AUTOSAR XML (schema 4-2-2)
package /STELLANTIS/EPT/ASWCs
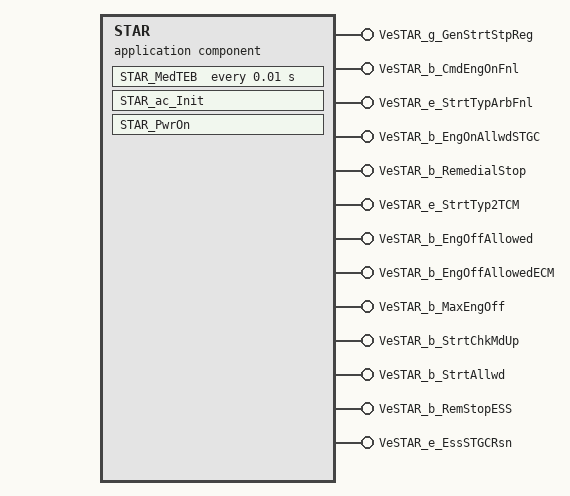
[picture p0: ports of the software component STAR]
  application sw component type STAR
    13 x provide port:
      VeSTAR_g_GenStrtStpReg: nonqueued-sender-com-spec{data-element=Value, init-value=0}, provided-interface=VeSTAR_g_GenStrtStpReg
      VeSTAR_b_CmdEngOnFnl: nonqueued-sender-com-spec{data-element=Value, init-value=0}, provided-interface=VeSTAR_b_CmdEngOnFnl
      VeSTAR_e_StrtTypArbFnl: nonqueued-sender-com-spec{data-element=Value, init-value=CeSTRR_e_NoAction}, provided-interface=VeSTAR_e_StrtTypArbFnl
      VeSTAR_b_EngOnAllwdSTGC: nonqueued-sender-com-spec{data-element=Value, init-value=0}, provided-interface=VeSTAR_b_EngOnAllwdSTGC
      VeSTAR_b_RemedialStop: nonqueued-sender-com-spec{data-element=Value, init-value=0}, provided-interface=VeSTAR_b_RemedialStop
      VeSTAR_e_StrtTyp2TCM: nonqueued-sender-com-spec{data-element=Value, init-value=CeSTRR_e_NoAction}, provided-interface=VeSTAR_e_StrtTyp2TCM
      VeSTAR_b_EngOffAllowed: nonqueued-sender-com-spec{data-element=Value, init-value=0}, provided-interface=VeSTAR_b_EngOffAllowed
      VeSTAR_b_EngOffAllowedECM: nonqueued-sender-com-spec{data-element=Value, init-value=0}, provided-interface=VeSTAR_b_EngOffAllowedECM
      VeSTAR_b_MaxEngOff: nonqueued-sender-com-spec{data-element=Value, init-value=0}, provided-interface=VeSTAR_b_MaxEngOff
      VeSTAR_b_StrtChkMdUp: nonqueued-sender-com-spec{data-element=Value, init-value=0}, provided-interface=VeSTAR_b_StrtChkMdUp
      VeSTAR_b_StrtAllwd: nonqueued-sender-com-spec{data-element=Value, init-value=0}, provided-interface=VeSTAR_b_StrtAllwd
      VeSTAR_b_RemStopESS: nonqueued-sender-com-spec{data-element=Value, init-value=0}, provided-interface=VeSTAR_b_RemStopESS
      VeSTAR_e_EssSTGCRsn: nonqueued-sender-com-spec{data-element=Value, init-value=CeSTRR_e_None}, provided-interface=VeSTAR_e_EssSTGCRsn
    behavior IB_STAR: data-type-mapping=msADTtoIDTMapping, handle-termination-and-restart=NO-SUPPORT
      timing event Event_MedTEB: start-on-event=STAR_MedTEB, period=0.01
      init event Event_STAR_ac_Init: start-on-event=STAR_ac_Init
      init event Event_PwrOn: start-on-event=STAR_PwrOn
      runnable STAR_ac_Init
        data-send-points:
          access OUT_VeSTAR_e_StrtTypArbFnl_Value: accessed-variable=VeSTAR_e_StrtTypArbFnl.Value
          access OUT_VeSTAR_e_StrtTyp2TCM_Value: accessed-variable=VeSTAR_e_StrtTyp2TCM.Value
          access OUT_VeSTAR_e_EssSTGCRsn_Value: accessed-variable=VeSTAR_e_EssSTGCRsn.Value
      runnable STAR_MedTEB
        data-send-points:
          13 x access:
            OUT_VeSTAR_b_EngOffAllowedECM_Value: accessed-variable=VeSTAR_b_EngOffAllowedECM.Value
            OUT_VeSTAR_b_MaxEngOff_Value: accessed-variable=VeSTAR_b_MaxEngOff.Value
            OUT_VeSTAR_b_StrtChkMdUp_Value: accessed-variable=VeSTAR_b_StrtChkMdUp.Value
            OUT_VeSTAR_e_EssSTGCRsn_Value: accessed-variable=VeSTAR_e_EssSTGCRsn.Value
            OUT_VeSTAR_e_StrtTypArbFnl_Value: accessed-variable=VeSTAR_e_StrtTypArbFnl.Value
            OUT_VeSTAR_e_StrtTyp2TCM_Value: accessed-variable=VeSTAR_e_StrtTyp2TCM.Value
            OUT_VeSTAR_b_StrtAllwd_Value: accessed-variable=VeSTAR_b_StrtAllwd.Value
            OUT_VeSTAR_b_CmdEngOnFnl_Value: accessed-variable=VeSTAR_b_CmdEngOnFnl.Value
            OUT_VeSTAR_b_EngOnAllwdSTGC_Value: accessed-variable=VeSTAR_b_EngOnAllwdSTGC.Value
            OUT_VeSTAR_b_RemedialStop_Value: accessed-variable=VeSTAR_b_RemedialStop.Value
            OUT_VeSTAR_b_EngOffAllowed_Value: accessed-variable=VeSTAR_b_EngOffAllowed.Value
            OUT_VeSTAR_b_RemStopESS_Value: accessed-variable=VeSTAR_b_RemStopESS.Value
            OUT_VeSTAR_g_GenStrtStpReg_Value: accessed-variable=VeSTAR_g_GenStrtStpReg.Value
      runnable STAR_PwrOn
        data-send-points:
          13 x access:
            OUT_VeSTAR_g_GenStrtStpReg_Value: accessed-variable=VeSTAR_g_GenStrtStpReg.Value
            OUT_VeSTAR_b_CmdEngOnFnl_Value: accessed-variable=VeSTAR_b_CmdEngOnFnl.Value
            OUT_VeSTAR_e_StrtTypArbFnl_Value: accessed-variable=VeSTAR_e_StrtTypArbFnl.Value
            OUT_VeSTAR_b_EngOnAllwdSTGC_Value: accessed-variable=VeSTAR_b_EngOnAllwdSTGC.Value
            OUT_VeSTAR_b_RemedialStop_Value: accessed-variable=VeSTAR_b_RemedialStop.Value
            OUT_VeSTAR_e_StrtTyp2TCM_Value: accessed-variable=VeSTAR_e_StrtTyp2TCM.Value
            OUT_VeSTAR_b_EngOffAllowed_Value: accessed-variable=VeSTAR_b_EngOffAllowed.Value
            OUT_VeSTAR_b_EngOffAllowedECM_Value: accessed-variable=VeSTAR_b_EngOffAllowedECM.Value
            OUT_VeSTAR_b_MaxEngOff_Value: accessed-variable=VeSTAR_b_MaxEngOff.Value
            OUT_VeSTAR_b_StrtChkMdUp_Value: accessed-variable=VeSTAR_b_StrtChkMdUp.Value
            OUT_VeSTAR_b_StrtAllwd_Value: accessed-variable=VeSTAR_b_StrtAllwd.Value
            OUT_VeSTAR_b_RemStopESS_Value: accessed-variable=VeSTAR_b_RemStopESS.Value
            OUT_VeSTAR_e_EssSTGCRsn_Value: accessed-variable=VeSTAR_e_EssSTGCRsn.Value
      variation point proxy Variant_STAR_BEVVar: category=CONDITION, condition-access=1
      variation point proxy Variant_STAR_StrtDvc2p5Eqpd: category=CONDITION, condition-access=0
